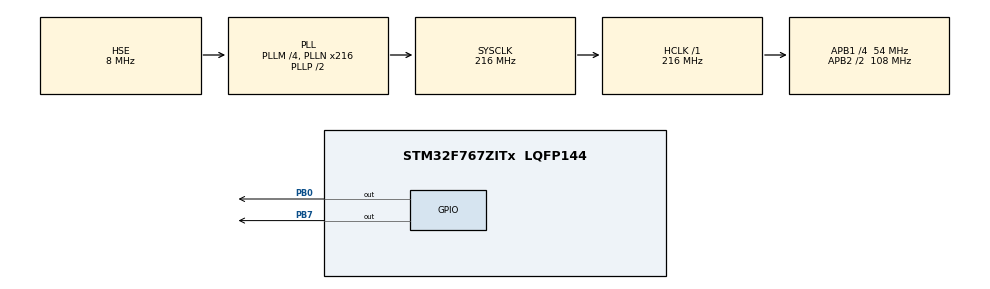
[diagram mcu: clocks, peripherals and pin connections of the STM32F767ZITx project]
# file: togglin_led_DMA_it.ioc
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Dma.MEMTOMEM.0.Direction=DMA_MEMORY_TO_MEMORY
Dma.MEMTOMEM.0.FIFOMode=DMA_FIFOMODE_ENABLE
Dma.MEMTOMEM.0.FIFOThreshold=DMA_FIFO_THRESHOLD_FULL
Dma.MEMTOMEM.0.Instance=DMA2_Stream0
Dma.MEMTOMEM.0.MemBurst=DMA_MBURST_SINGLE
Dma.MEMTOMEM.0.MemDataAlignment=DMA_MDATAALIGN_BYTE
Dma.MEMTOMEM.0.MemInc=DMA_MINC_DISABLE
Dma.MEMTOMEM.0.Mode=DMA_NORMAL
Dma.MEMTOMEM.0.PeriphBurst=DMA_PBURST_SINGLE
Dma.MEMTOMEM.0.PeriphDataAlignment=DMA_PDATAALIGN_BYTE
Dma.MEMTOMEM.0.PeriphInc=DMA_PINC_DISABLE
Dma.MEMTOMEM.0.Priority=DMA_PRIORITY_LOW
Dma.Request0=MEMTOMEM
Mcu.Family=STM32F7
Mcu.Name=STM32F767ZITx
Mcu.Package=LQFP144
NVIC.DMA2_Stream0_IRQn=true\:0\:0\:false\:false\:true\:true\:true\:true
NVIC.PriorityGroup=NVIC_PRIORITYGROUP_4
PA13.Mode=Serial_Wire
PA13.Signal=SYS_JTMS-SWDIO
PA14.Mode=Serial_Wire
PA14.Signal=SYS_JTCK-SWCLK
PB0.Signal=GPIO_Output
PB7.Signal=GPIO_Output
PH0/OSC_IN.Mode=HSE-External-Oscillator
PH0/OSC_IN.Signal=RCC_OSC_IN
PH1/OSC_OUT.Mode=HSE-External-Oscillator
PH1/OSC_OUT.Signal=RCC_OSC_OUT
ProjectManager.HeapSize=0x200
ProjectManager.StackSize=0x400
ProjectManager.TargetToolchain=STM32CubeIDE
RCC.AHBFreq_Value=216000000
RCC.APB1CLKDivider=RCC_HCLK_DIV4
RCC.APB1Freq_Value=54000000
RCC.APB1TimFreq_Value=108000000
RCC.APB2CLKDivider=RCC_HCLK_DIV2
RCC.APB2Freq_Value=108000000
RCC.APB2TimFreq_Value=216000000
RCC.CortexFreq_Value=216000000
RCC.HCLKFreq_Value=216000000
RCC.HSE_VALUE=8000000
RCC.HSI_VALUE=16000000
RCC.LSE_VALUE=32768
RCC.PLLM=4
RCC.PLLN=216
RCC.PLLSourceVirtual=RCC_PLLSOURCE_HSE
RCC.SYSCLKFreq_VALUE=216000000
RCC.SYSCLKSource=RCC_SYSCLKSOURCE_PLLCLK
RCC.USBFreq_Value=216000000
RCC.VCOOutputFreq_Value=432000000
board=custom

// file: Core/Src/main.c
/* USER CODE BEGIN Header */
/**
  ******************************************************************************
  * @file           : main.c
  * @brief          : Main program body
  ******************************************************************************
  * @attention
  *
  * Copyright (c) 2025 STMicroelectronics.
  * All rights reserved.
  *
  * This software is licensed under terms that can be found in the LICENSE file
  * in the root directory of this software component.
  * If no LICENSE file comes with this software, it is provided AS-IS.
  *
  ******************************************************************************
  */
/* USER CODE END Header */
#include "main.h"
#include "dma.h"
#include "gpio.h"

void SystemClock_Config(void);
/* USER CODE BEGIN PFP */
void my_Dma_TC_cb( DMA_HandleTypeDef *pHandle);

/* USER CODE END PFP */

/* USER CODE BEGIN 0 */
uint8_t led_data[2] = {0x80, 0x00};
/* USER CODE END 0 */

int main(void)
{
  /* USER CODE BEGIN 1 */
	uint32_t current_ticks=0;
  /* USER CODE END 1 */

  /* MCU Configuration--------------------------------------------------------*/

  /* Reset of all peripherals, Initializes the Flash interface and the Systick. */
  HAL_Init();

  /* Configure the system clock */
  SystemClock_Config();

  /* Initialize all configured peripherals */
  MX_GPIO_Init();
  MX_DMA_Init();
  /* USER CODE BEGIN 2 */
  HAL_DMA_RegisterCallback(&hdma_memtomem_dma2_stream0,HAL_DMA_XFER_CPLT_CB_ID,&my_Dma_TC_cb);
  /* USER CODE END 2 */

  /* Infinite loop */
  while (1)
  {

    /* USER CODE BEGIN 3 */
	HAL_DMA_Start_IT(&hdma_memtomem_dma2_stream0,(uint32_t)&led_data[0],(uint32_t) &GPIOB->ODR,1);

	/*delay of 1 sec */
	current_ticks = HAL_GetTick();
	while( (current_ticks + 1000 ) >= HAL_GetTick() );

	HAL_DMA_Start_IT(&hdma_memtomem_dma2_stream0,(uint32_t)&led_data[1],(uint32_t) &GPIOB->ODR,1);

	/*delay of 1 sec */
	current_ticks = HAL_GetTick();
	while( (current_ticks + 1000 ) >= HAL_GetTick() );
  }
  /* USER CODE END 3 */
}

void SystemClock_Config(void)
{
  RCC_OscInitTypeDef RCC_OscInitStruct = {0};
  RCC_ClkInitTypeDef RCC_ClkInitStruct = {0};

  /** Configure the main internal regulator output voltage
  */
  __HAL_RCC_PWR_CLK_ENABLE();
  __HAL_PWR_VOLTAGESCALING_CONFIG(PWR_REGULATOR_VOLTAGE_SCALE1);

  /** Initializes the RCC Oscillators according to the specified parameters
  * in the RCC_OscInitTypeDef structure.
  */
  RCC_OscInitStruct.OscillatorType = RCC_OSCILLATORTYPE_HSE;
  RCC_OscInitStruct.HSEState = RCC_HSE_ON;
  RCC_OscInitStruct.PLL.PLLState = RCC_PLL_ON;
  RCC_OscInitStruct.PLL.PLLSource = RCC_PLLSOURCE_HSE;
  RCC_OscInitStruct.PLL.PLLM = 4;
  RCC_OscInitStruct.PLL.PLLN = 216;
  RCC_OscInitStruct.PLL.PLLP = RCC_PLLP_DIV2;
  RCC_OscInitStruct.PLL.PLLQ = 2;
  RCC_OscInitStruct.PLL.PLLR = 2;
  if (HAL_RCC_OscConfig(&RCC_OscInitStruct) != HAL_OK)
  {
    Error_Handler();
  }

  /** Activate the Over-Drive mode
  */
  if (HAL_PWREx_EnableOverDrive() != HAL_OK)
  {
    Error_Handler();
  }

  /** Initializes the CPU, AHB and APB buses clocks
  */
  RCC_ClkInitStruct.ClockType = RCC_CLOCKTYPE_HCLK|RCC_CLOCKTYPE_SYSCLK
                              |RCC_CLOCKTYPE_PCLK1|RCC_CLOCKTYPE_PCLK2;
  RCC_ClkInitStruct.SYSCLKSource = RCC_SYSCLKSOURCE_PLLCLK;
  RCC_ClkInitStruct.AHBCLKDivider = RCC_SYSCLK_DIV1;
  RCC_ClkInitStruct.APB1CLKDivider = RCC_HCLK_DIV4;
  RCC_ClkInitStruct.APB2CLKDivider = RCC_HCLK_DIV2;

  if (HAL_RCC_ClockConfig(&RCC_ClkInitStruct, FLASH_LATENCY_7) != HAL_OK)
  {
    Error_Handler();
  }
}

/* USER CODE BEGIN 4 */
void my_Dma_TC_cb( DMA_HandleTypeDef *pHandle)
{
	uint8_t volatile static status = 1;

	status = !status;
	HAL_GPIO_WritePin(GPIOB, GPIO_PIN_0, status);

}
/* USER CODE END 4 */

void Error_Handler(void)
{
  __disable_irq();
  while (1)
  {
  }
}
